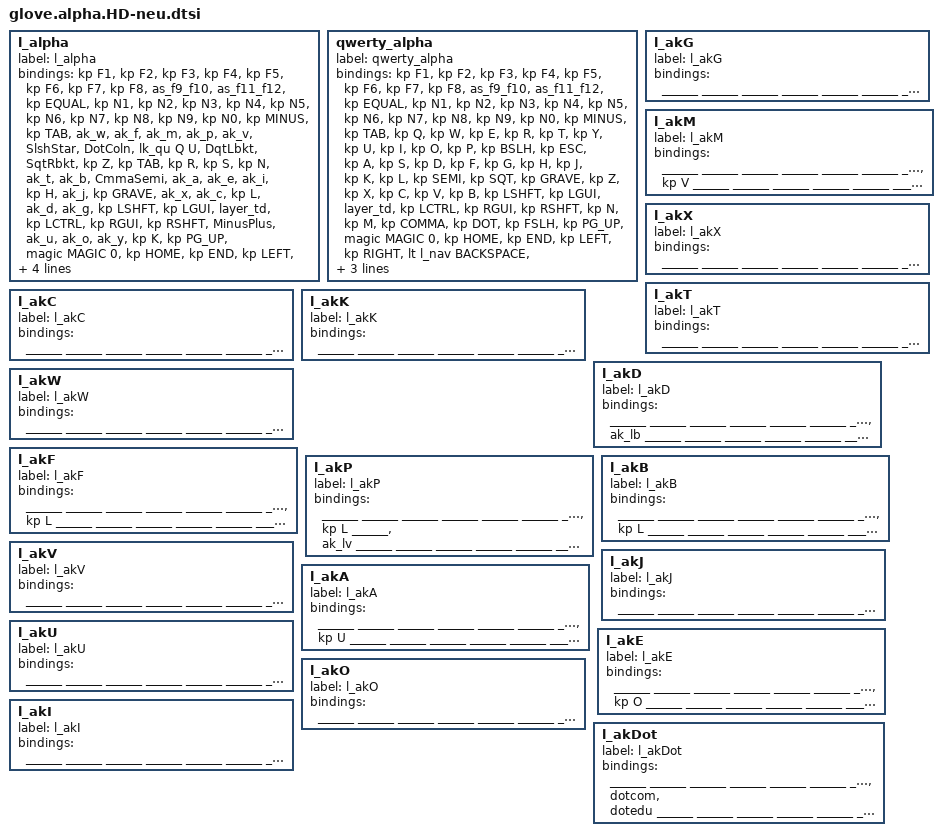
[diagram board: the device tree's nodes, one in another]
#define ______  &trans

/*    KEY POSITION Numbers for Zaphod
╭────────────────────╮ ╭────────────────────╮
│  0   1   2   3   4 │ │  5   6   7   8   9 │
│ 10  11  12  13  14 │ │ 15  16  17  18  19 |
| 20  21  22  23  24 │ │ 25  26  27  28  29 |
╰───────────╮ 30  31 | | 32  33  ╭──────────╯
╰────────╯ ╰─────────╯
*/
/*    KEY POSITION Names
╭─────────────────────╮ ╭─────────────────────────╮
│ LT4 LT3 LT2 LT1 LT0 │ │ RT0 RT1 RT2 RT3 RT4 RT5 │
│ LM4 LM3 LM2 LM1 LM0 │ │ RM0 RM1 RM2 RM3 RM4 RM5 │
│ LB4 LB3 LB2 LB1 LB0 │ │ RB0 RB1 RB2 RB3 RB4 RB5 │
╰───────────╮ LH2 LH1 | | RH1 RH2 ╭───────────────╯
╰─────────╯ ╰─────────╯
*/
/*  Base (alpha) Layer  Hands Down Vibranium-vb
Building for a 34 key board
╭─────────────────────╮ ╭─────────────────────────╮
│  w   f   m   p   v  │ │  /*   .:  Q  "[  ']   Z │
│  r   s   n   t   b  | |  ,;   A   E   I   H   J │
│  x   c   l   d   g  │ │  -+   U   O   Y   K     │
╰──────────╮      BSP │ │  SPC RET  ╭─────────────╯
		   ╰──────────╯ ╰───────────╯
*/

l_alpha {
	label = "l_alpha";
	bindings = <
	&kp F1          &kp F2      &kp F3      &kp F4      &kp F5                                                                                                                     &kp F6      &kp F7      &kp F8      &as_f9_f10  &as_f11_f12
	&kp EQUAL       &kp N1      &kp N2      &kp N3      &kp N4      &kp N5                                                                                             &kp N6      &kp N7      &kp N8      &kp N9      &kp N0      &kp MINUS
	&kp TAB         &ak_w       &ak_f       &ak_m       &ak_p       &ak_v                                                                                              &SlshStar   &DotColn    &lk_qu Q U  &DqtLbkt    &SqtRbkt    &kp Z
	&kp TAB         &kp R       &kp S       &kp N       &ak_t       &ak_b                                                                                              &CmmaSemi   &ak_a       &ak_e       &ak_i       &kp H       &ak_j
	&kp GRAVE       &ak_x       &ak_c       &kp L       &ak_d       &ak_g   &kp LSHFT     &kp LGUI       &layer_td  &kp LCTRL    &kp RGUI            &kp RSHFT         &MinusPlus  &ak_u       &ak_o       &ak_y       &kp K       &kp PG_UP
	&magic MAGIC 0  &kp HOME    &kp END     &kp LEFT    &kp RIGHT           &lt l_nav BACKSPACE   &lt l_fun LCTRL   &kp LALT   &kp LALT     &lt l_nav RETURN    &lt l_sym SPACE               &kp UP      &kp DOWN    &kp LBKT    &kp RBKT    &kp PG_DN
	>;
};
qwerty_alpha {
	label = "qwerty_alpha";
            // ---------------------------------------------------------------------------------------------------------------------------------
            // |  F1   |  F2 |  F3 |  F4  |  F5  |                                                               |  F6   |  F7   |  F8  |   F9  |  F10 |
            // |  =    |  1  |  2  |  3   |  4   |  5   |                                                 |  6   |   7   |   8   |  9   |   0   |   -  |
            // |  TAB  |  Q  |  W  |  E   |  R   |  T   |                                                 |  Y   |   U   |   I   |  O   |   P   |   \  |
            // |  ESC  |  A  |  S  |  D   |  F   |  G   |                                                 |  H   |   J   |   K   |  L   |   ;   |   '  |
            // |   `   |  Z  |  X  |  C   |  V   |  B   | LSHFT | LGUI | LOWER | | LCTRL  | RGUI | RSHFT |  N   |   M   |   ,   |  .   |   /   | PGUP |
            // | MAGIC | HOME| END | LEFT | RIGHT|      | BSPC  | LCTRL   | LALT  | | LALT  | RET   | SPACE |      |  UP   | DOWN  |  [   |   ]   | PGDN |

            bindings = <
            &kp F1         &kp F2   &kp F3      &kp F4      &kp F5                                                                                         &kp F6  &kp F7      &kp F8      &as_f9_f10      &as_f11_f12
            &kp EQUAL      &kp N1   &kp N2      &kp N3      &kp N4      &kp N5                                                                     &kp N6  &kp N7  &kp N8      &kp N9      &kp N0      &kp MINUS
            &kp TAB        &kp Q    &kp W       &kp E       &kp R       &kp T                                                                      &kp Y   &kp U   &kp I       &kp O       &kp P       &kp BSLH
            &kp ESC        &kp A    &kp S       &kp D       &kp F       &kp G                                                                      &kp H   &kp J   &kp K       &kp L       &kp SEMI    &kp SQT
            &kp GRAVE      &kp Z    &kp X       &kp C       &kp V       &kp B   &kp LSHFT     &kp LGUI       &layer_td  &kp LCTRL    &kp RGUI            &kp RSHFT   &kp N   &kp M   &kp COMMA   &kp DOT     &kp FSLH    &kp PG_UP
            &magic MAGIC 0 &kp HOME &kp END     &kp LEFT    &kp RIGHT           &lt l_nav BACKSPACE   &lt l_fun LCTRL   &kp LALT   &kp LALT     &lt l_nav RETURN  &lt l_sym SPACE         &kp UP  &kp DOWN    &kp LBKT    &kp RBKT    &kp PG_DN
            >;
        };
l_akG {
	label = "l_akG";
	bindings = <
	______  ______  ______  ______  ______                                                                  ______  ______  ______  ______  ______
	______  ______  ______  ______  ______  ______                                                          ______  ______  ______  ______  ______  ______
	______  ______  ______  ______  ______  ______                                                          ______  ______  ______  ______  ______  ______
	______  ______  ______  ______  ______  ______                                                          ______  ______  ______  ______  ______  ______
	______  ______  ______  ______  ______  ______       ______  ______  ______  ______  ______  ______     ______  ______  ______  ______  ______  ______
	______  ______  ______  ______  ______               ______  ______  ______  ______  ______  ______     ______  ______  ______  ______  ______
	>;
};
l_akM {
	label = "l_akM";
	bindings = <
	
	______  ______  ______  ______  ______                                                                  ______  ______  ______  ______  ______
	______  ______  ______  ______  ______  ______                                                          ______  ______  ______  ______  ______   ______
	______  ______  ______  ______  ______  &kp V                                                          ______  ______  ______  ______  ______   ______
	______  ______  ______  ______  ______  ______                                                          ______  ______  ______  ______  ______   ______
	______  ______  ______  ______  ______  ______       ______  ______  ______  ______  ______  ______     ______  ______  ______  ______  ______   ______
	______  ______  ______  ______  ______               ______  ______  ______  ______  ______  ______     ______  ______  ______  ______  ______
	>;
};
l_akX {
	label = "l_akX";
	bindings = <
	
	______  ______  ______  ______  ______                                                                  ______  ______  ______  ______  ______
	______  ______  ______  ______  ______  ______                                                          ______  ______  ______  ______  ______   ______
	______  ______  ______  ______  ______  ______                                                          ______  ______  ______  ______  ______   ______
	______  ______  ______  ______  ______  ______                                                          ______  ______  ______  ______  ______   ______
	______  ______  ______  ______  ______  ______       ______  ______  ______  ______  ______  ______     ______  ______  ______  ______  ______   ______
	______  ______  ______  ______  ______               ______  ______  ______  ______  ______  ______     ______  ______  ______  ______  ______
	>;
};
l_akT {
	label = "l_akT";
	bindings = <
	
	______  ______  ______  ______  ______                                                                  ______  ______  ______  ______  ______
	______  ______  ______  ______  ______  ______                                                          ______  ______  ______  ______  ______   ______
	______  ______  ______  ______  ______  ______                                                          ______  ______  ______  ______  ______   ______
	______  ______  ______  ______  ______  ______                                                          ______  ______  ______  ______  ______   ______
	______  ______  ______  ______  ______  ______       ______  ______  ______  ______  ______  ______     ______  ______  ______  ______  ______   ______
	______  ______  ______  ______  ______               ______  ______  ______  ______  ______  ______     ______  ______  ______  ______  ______
	>;
};
l_akC {
	label = "l_akC";
	bindings = <
	
	______  ______  ______  ______  ______                                                                  ______  ______  ______  ______  ______
	______  ______  ______  ______  ______  ______                                                          ______  ______  ______  ______  ______   ______
	______  ______  ______  ______  ______  ______                                                          ______  ______  ______  ______  ______   ______
	______  ______  ______  ______  ______  ______                                                          ______  ______  ______  ______  ______   ______
	______  ______  ______  ______  ______  ______       ______  ______  ______  ______  ______  ______     ______  ______  ______  ______  ______   ______
	______  ______  ______  ______  ______               ______  ______  ______  ______  ______  ______     ______  ______  ______  ______  ______
	>;
};
l_akK {
	label = "l_akK";
	bindings = <
	
	______  ______  ______  ______  ______                                                                  ______  ______  ______  ______  ______
	______  ______  ______  ______  ______  ______                                                          ______  ______  ______  ______  ______   ______
	______  ______  ______  ______  ______  ______                                                          ______  ______  ______  ______  ______   ______
	______  ______  ______  ______  ______  ______                                                          ______  ______  ______  ______  ______   ______
	______  ______  ______  ______  ______  ______       ______  ______  ______  ______  ______  ______     ______  ______  ______  ______  ______   ______
	______  ______  ______  ______  ______               ______  ______  ______  ______  ______  ______     ______  ______  ______  ______  ______
	>;
};
l_akD {
	label = "l_akD";
	bindings = <
	
	______  ______  ______  ______  ______                                                                  ______  ______  ______  ______  ______
	______  ______  ______  ______  ______  ______                                                          ______  ______  ______  ______  ______   ______
	______  ______  ______  ______  ______  ______                                                          ______  ______  ______  ______  ______   ______
	______  ______  ______  ______  ______  &ak_lb                                                          ______  ______  ______  ______  ______   ______
	______  ______  ______  ______  ______  ______       ______  ______  ______  ______  ______  ______     ______  ______  ______  ______  ______   ______
	______  ______  ______  ______  ______               ______  ______  ______  ______  ______  ______     ______  ______  ______  ______  ______
	>;
};
l_akW {
	label = "l_akW";
	bindings = <
	
	______  ______  ______  ______  ______                                                                  ______  ______  ______  ______  ______
	______  ______  ______  ______  ______  ______                                                          ______  ______  ______  ______  ______   ______
	______  ______  ______  ______  ______  ______                                                          ______  ______  ______  ______  ______   ______
	______  ______  ______  ______  ______  ______                                                          ______  ______  ______  ______  ______   ______
	______  ______  ______  ______  ______  ______       ______  ______  ______  ______  ______  ______     ______  ______  ______  ______  ______   ______
	______  ______  ______  ______  ______               ______  ______  ______  ______  ______  ______     ______  ______  ______  ______  ______
	>;
};
l_akF {
	label = "l_akF";
	bindings = <
	______  ______  ______  ______  ______                                                                  ______  ______  ______  ______  ______
	______  ______  ______  ______  ______  ______                                                          ______  ______  ______  ______  ______   ______
	______  ______  ______  &kp L   ______  ______                                                          ______  ______  ______  ______  ______   ______
	______  ______  ______  ______  ______  ______                                                          ______  ______  ______  ______  ______   ______
	______  ______  ______  ______  ______  ______       ______  ______  ______  ______  ______  ______     ______  ______  ______  ______  ______   ______
	______  ______  ______  ______  ______               ______  ______  ______  ______  ______  ______     ______  ______  ______  ______  ______
	>;
};
l_akP {
	label = "l_akP";
	bindings = <
	
	______  ______  ______  ______  ______                                                                  ______  ______  ______  ______  ______
	______  ______  ______  ______  ______  ______                                                          ______  ______  ______  ______  ______   ______
	______  ______  ______  &kp L   ______  &ak_lv                                                          ______  ______  ______  ______  ______   ______
	______  ______  ______  ______  ______  ______                                                          ______  ______  ______  ______  ______   ______
	______  ______  ______  ______  ______  ______       ______  ______  ______  ______  ______  ______     ______  ______  ______  ______  ______   ______
	______  ______  ______  ______  ______               ______  ______  ______  ______  ______  ______     ______  ______  ______  ______  ______
	>;
};
l_akB {
	label = "l_akB";
	bindings = <
	
	______  ______  ______  ______  ______                                                                  ______  ______  ______  ______  ______
	______  ______  ______  ______  ______  ______                                                          ______  ______  ______  ______  ______   ______
	______  ______  ______  ______  ______  ______                                                          ______  ______  ______  ______  ______   ______
	______  ______  ______  ______  ______  ______                                                          ______  ______  ______  ______  ______   ______
	______  ______  ______  ______  &kp L   ______       ______  ______  ______  ______  ______  ______     ______  ______  ______  ______  ______   ______
	______  ______  ______  ______  ______               ______  ______  ______  ______  ______  ______     ______  ______  ______  ______  ______
	>;
};
l_akV {
	label = "l_akV";
	bindings = <
	
	______  ______  ______  ______  ______                                                                  ______  ______  ______  ______  ______
	______  ______  ______  ______  ______  ______                                                          ______  ______  ______  ______  ______   ______
	______  ______  ______  ______  ______  ______                                                          ______  ______  ______  ______  ______   ______
	______  ______  ______  ______  ______  ______                                                          ______  ______  ______  ______  ______   ______
	______  ______  ______  ______  ______  ______       ______  ______  ______  ______  ______  ______     ______  ______  ______  ______  ______   ______
	______  ______  ______  ______  ______               ______  ______  ______  ______  ______  ______     ______  ______  ______  ______  ______
	>;
};
l_akJ {
	label = "l_akJ";
	bindings = <
	
	______  ______  ______  ______  ______                                                                  ______  ______  ______  ______  ______
	______  ______  ______  ______  ______  ______                                                          ______  ______  ______  ______  ______   ______
	______  ______  ______  ______  ______  ______                                                          ______  ______  ______  ______  ______   ______
	______  ______  ______  ______  ______  ______                                                          ______  ______  ______  ______  ______   ______
	______  ______  ______  ______  ______  ______       ______  ______  ______  ______  ______  ______     ______  ______  ______  ______  ______   ______
	______  ______  ______  ______  ______               ______  ______  ______  ______  ______  ______     ______  ______  ______  ______  ______
	>;
};
l_akA {
	label = "l_akA";
	bindings = <
	
	______  ______  ______  ______  ______                                                                  ______  ______  ______  ______  ______
	______  ______  ______  ______  ______  ______                                                          ______  ______  ______  ______  ______   ______
	______  ______  ______  ______  ______  ______                                                          ______  ______  ______  ______  ______   ______
	______  ______  ______  ______  ______  ______                                                          ______  ______  ______  ______  &kp U    ______
	______  ______  ______  ______  ______  ______       ______  ______  ______  ______  ______  ______     ______  ______  ______  ______  ______   ______
	______  ______  ______  ______  ______               ______  ______  ______  ______  ______  ______     ______  ______  ______  ______  ______
	>;
};

l_akU {
	label = "l_akU";
	bindings = <
	
	______  ______  ______  ______  ______                                                                  ______  ______  ______  ______  ______
	______  ______  ______  ______  ______  ______                                                          ______  ______  ______  ______  ______   ______
	______  ______  ______  ______  ______  ______                                                          ______  ______  ______  ______  ______   ______
	______  ______  ______  ______  ______  ______                                                          ______  ______  ______  ______  ______   ______
	______  ______  ______  ______  ______  ______       ______  ______  ______  ______  ______  ______     ______  ______  ______  ______  ______   ______
	______  ______  ______  ______  ______               ______  ______  ______  ______  ______  ______     ______  ______  ______  ______  ______
	>;
};

l_akE {
	label = "l_akE";
	bindings = <
	
	______  ______  ______  ______  ______                                                                  ______  ______  ______  ______  ______
	______  ______  ______  ______  ______  ______                                                          ______  ______  ______  ______  ______   ______
	______  ______  ______  ______  ______  ______                                                          ______  ______  ______  ______  ______   ______
	______  ______  ______  ______  ______  ______                                                          ______  ______  ______  ______  &kp O    ______
	______  ______  ______  ______  ______  ______       ______  ______  ______  ______  ______  ______     ______  ______  ______  ______  ______   ______
	______  ______  ______  ______  ______               ______  ______  ______  ______  ______  ______     ______  ______  ______  ______  ______
	>;
};
l_akO {
	label = "l_akO";
	bindings = <
	
	______  ______  ______  ______  ______                                                                  ______  ______  ______  ______  ______
	______  ______  ______  ______  ______  ______                                                          ______  ______  ______  ______  ______   ______
	______  ______  ______  ______  ______  ______                                                          ______  ______  ______  ______  ______   ______
	______  ______  ______  ______  ______  ______                                                          ______  ______  ______  ______  ______   ______
	______  ______  ______  ______  ______  ______       ______  ______  ______  ______  ______  ______     ______  ______  ______  ______  ______   ______
	______  ______  ______  ______  ______               ______  ______  ______  ______  ______  ______     ______  ______  ______  ______  ______
	>;
};
l_akI {
	label = "l_akI";
	bindings = <
	
	______  ______  ______  ______  ______                                                                  ______  ______  ______  ______  ______
	______  ______  ______  ______  ______  ______                                                          ______  ______  ______  ______  ______   ______
	______  ______  ______  ______  ______  ______                                                          ______  ______  ______  ______  ______   ______
	______  ______  ______  ______  ______  ______                                                          ______  ______  ______  ______  ______   ______
	______  ______  ______  ______  ______  ______       ______  ______  ______  ______  ______  ______     ______  ______  ______  ______  ______   ______
	______  ______  ______  ______  ______               ______  ______  ______  ______  ______  ______     ______  ______  ______  ______  ______
	>;
};

l_akDot {
	label = "l_akDot";
	bindings = <
	
	______  ______  ______  ______  ______                                                                  ______  ______  ______  ______  ______
	______  ______  ______  ______  ______  ______                                                          ______  ______  ______  ______  ______   ______
	______  ______  ______  ______  ______  ______                                                          ______  ______  ______  &dotcom &dotedu  ______
	______  ______  ______  ______  ______  ______                                                          ______  ______  ______  ______  ______   ______
	______  ______  ______  ______  ______  ______       ______  ______  ______  ______  ______  ______     ______  ______  ______  ______  ______   ______
	______  ______  ______  ______  ______               ______  ______  ______  ______  ______  ______     ______  ______  ______  ______  ______
	>;
};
